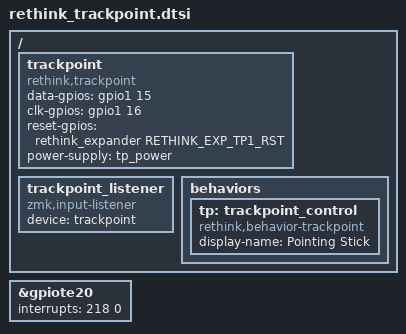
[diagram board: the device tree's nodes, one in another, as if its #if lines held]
/*
 * Copyright (c) 2026 Ziemniaczenka
 * SPDX-License-Identifier: MIT
 *
 * TP1 pointing stick (Mezzanine 37-40, FFC1 J5), for keyboard shields. Include
 * after rethink_adapter.dtsi. For the FFC2 stick (TP2, J8), a shield sets tp2
 * and TP2_RST on &trackpoint (rethink_t480, rethink_e580). FW_DAT and FW_CLK reach the stick through the
 * PCA9306 level shifter (JP4/JP5 1-2) or directly (2-3). Its movement and
 * buttons go to ZMK as a mouse (CONFIG_ZMK_POINTING, on by default for
 * shields with this node). Keys control it with &tp TP_OFF, TP_ON, TP_TOG,
 * TP_RECAL, TP_RATE_UP, TP_RATE_DN, TP_PTS_TOG and TP_SCROLL_TOG (#include
 * <dt-bindings/rethink/trackpoint.h> in the keymap).
 */

/ {
    trackpoint: trackpoint {
        compatible = "rethink,trackpoint";
        data-gpios = <&gpio1 15 (GPIO_ACTIVE_HIGH | GPIO_OPEN_DRAIN)>;
        clk-gpios = <&gpio1 16 (GPIO_ACTIVE_HIGH | GPIO_OPEN_DRAIN)>;
        reset-gpios = <&rethink_expander RETHINK_EXP_TP1_RST 0>;
        power-supply = <&tp_power>;
    };

    trackpoint_listener: trackpoint_listener {
        compatible = "zmk,input-listener";
        device = <&trackpoint>;
    };

    behaviors {
        tp: trackpoint_control {
            compatible = "rethink,behavior-trackpoint";
            #binding-cells = <1>;
            display-name = "Pointing Stick";
        };
    };
};

// FW_CLK's falling edges (P1, GPIOTE20) at priority 0, beside the Bluetooth
// controller's lower layer: at the default 1, the controller's upper layer
// delays them by more than one clock period (68 µs) and bits are lost
&gpiote20 {
#ifdef USE_NON_SECURE_ADDRESS_MAP
    interrupts = <218 0>;
#else
    interrupts = <219 0>;
#endif
};
